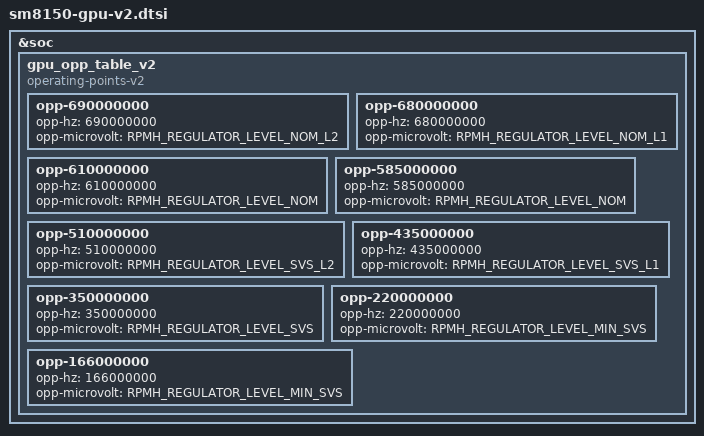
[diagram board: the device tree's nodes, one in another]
/* Copyright (c) 2018-2019, The Linux Foundation. All rights reserved.
 *
 * This program is free software; you can redistribute it and/or modify
 * it under the terms of the GNU General Public License version 2 and
 * only version 2 as published by the Free Software Foundation.
 *
 * This program is distributed in the hope that it will be useful,
 * but WITHOUT ANY WARRANTY; without even the implied warranty of
 * MERCHANTABILITY or FITNESS FOR A PARTICULAR PURPOSE.  See the
 * GNU General Public License for more details.
 */

&soc {
	gpu_opp_table_v2: gpu_opp_table_v2 {
		compatible = "operating-points-v2";

		opp-690000000 {
			opp-hz = /bits/ 64 <690000000>;
			opp-microvolt = <RPMH_REGULATOR_LEVEL_NOM_L2>;
		};
		
		opp-680000000 {
			opp-hz = /bits/ 64 <680000000>;
			opp-microvolt = <RPMH_REGULATOR_LEVEL_NOM_L1>;
		};
		
		opp-610000000 {
			opp-hz = /bits/ 64 <610000000>;
			opp-microvolt = <RPMH_REGULATOR_LEVEL_NOM>;
		};

		opp-585000000 {
			opp-hz = /bits/ 64 <585000000>;
			opp-microvolt = <RPMH_REGULATOR_LEVEL_NOM>;
		};

		opp-510000000 {
			opp-hz = /bits/ 64 <510000000>;
			opp-microvolt = <RPMH_REGULATOR_LEVEL_SVS_L2>;
		};

		opp-435000000 {
			opp-hz = /bits/ 64 <435000000>;
			opp-microvolt = <RPMH_REGULATOR_LEVEL_SVS_L1>;
		};

		opp-350000000 {
			opp-hz = /bits/ 64 <350000000>;
			opp-microvolt = <RPMH_REGULATOR_LEVEL_SVS>;
		};

		opp-220000000 {
			opp-hz = /bits/ 64 <220000000>;
			opp-microvolt = <RPMH_REGULATOR_LEVEL_MIN_SVS>;
		};

		opp-166000000 {
			opp-hz = /bits/ 64 <166000000>;
			opp-microvolt = <RPMH_REGULATOR_LEVEL_MIN_SVS>;
		};
	};
};
